# AT32F423 register map
Vendor: Keil; Series: AT32F423; File version: 1.0
CPU: CM4 r0p1, little endian, no MPU, FPU, 4 interrupt priority bits
Registers are 32-bit, read-write, reset 0x0 unless marked. A register's access mark holds for its fields unless they carry their own. Offsets are from the block's base; [hi:lo] are bit positions; 'fields as' and 'values as' point back to an identical list.

## XMC — Flexible static memory controller
Base 0xA0000000
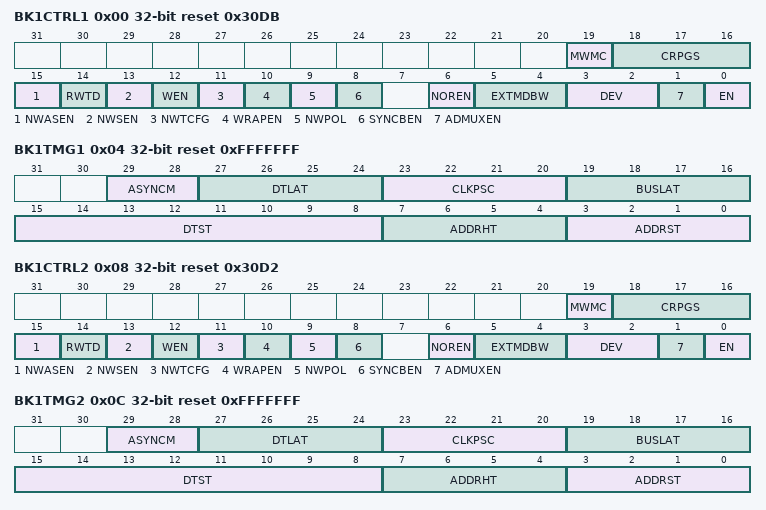
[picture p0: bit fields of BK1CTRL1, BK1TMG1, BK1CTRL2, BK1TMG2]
0x00 BK1CTRL1 reset 0x30DB — SRAM/NOR-Flash chip-select control register 1
  [19] MWMC — Memory write mode control
  [18:16] CRPGS — CRAM page size
  [15] NWASEN — NWAIT in asynchronous transfer enable
  [14] RWTD — Read-write timing different
  [13] NWSEN — NWAIT in synchronous transfer enable
  [12] WEN — Write enable
  [11] NWTCFG — Wait timing configuration
  [10] WRAPEN — Wrapped enable
  [9] NWPOL — NWAIT polarity
  [8] SYNCBEN — Synchronous burst enable
  [6] NOREN — Nor flash access enable
  [5:4] EXTMDBW — External memory data bus width
  [3:2] DEV — Memory device type
  [1] ADMUXEN — Address and data multiplexing enable
  [0] EN — Memory bank enable
0x04 BK1TMG1 reset 0xFFFFFFF — SRAM/NOR-Flash chip-select timing register 1
  [29:28] ASYNCM — Asynchronous mode
  [27:24] DTLAT — Data latency
  [23:20] CLKPSC — Clock prescale
  [19:16] BUSLAT — Bus latency
  [15:8] DTST — Asynchronous data setup time
  [7:4] ADDRHT — Address-hold time
  [3:0] ADDRST — Address setup time
0x08 BK1CTRL2 reset 0x30D2 — SRAM/NOR-Flash chip-select control register 2
  fields as BK1CTRL1
0x0C BK1TMG2 reset 0xFFFFFFF — SRAM/NOR-Flash chip-select timing register 2
  fields as BK1TMG1
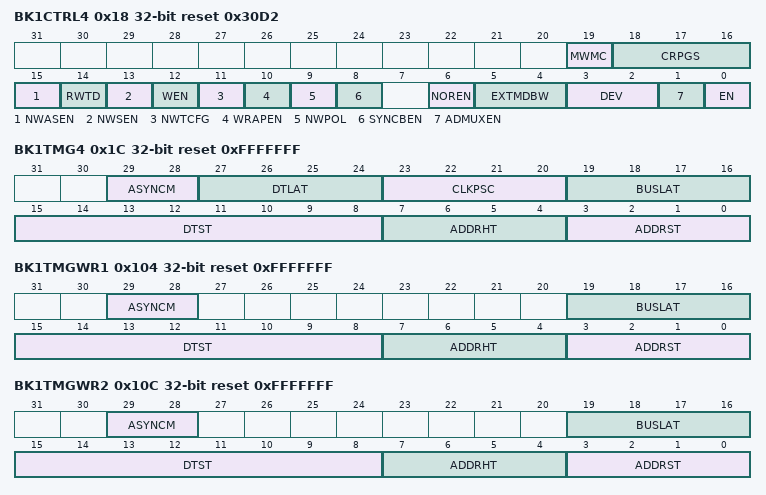
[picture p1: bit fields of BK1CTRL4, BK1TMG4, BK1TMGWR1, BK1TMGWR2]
0x18 BK1CTRL4 reset 0x30D2 — SRAM/NOR-Flash chip-select control register 4
  fields as BK1CTRL1
0x1C BK1TMG4 reset 0xFFFFFFF — SRAM/NOR-Flash chip-select timing register 4
  fields as BK1TMG1
0x104 BK1TMGWR1 reset 0xFFFFFFF — SRAM/NOR-Flash write timing registers 1
  [29:28] ASYNCM — Asynchronous mode
  [19:16] BUSLAT — Bus latency
  [15:8] DTST — Asynchronous data setup time
  [7:4] ADDRHT — Address-hold time
  [3:0] ADDRST — Address setup time
0x10C BK1TMGWR2 reset 0xFFFFFFF — SRAM/NOR-Flash write timing registers 2
  fields as BK1TMGWR1
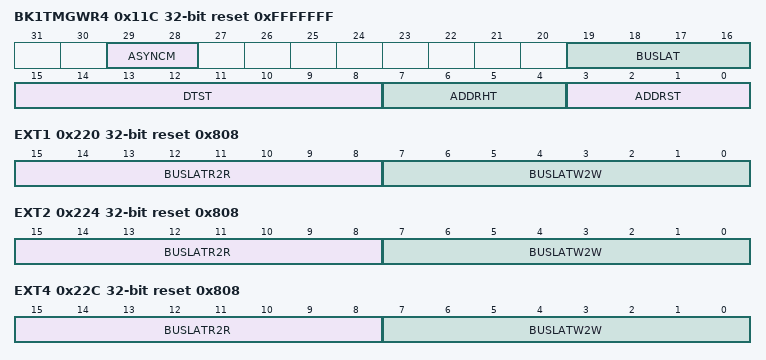
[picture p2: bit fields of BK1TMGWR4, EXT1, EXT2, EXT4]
0x11C BK1TMGWR4 reset 0xFFFFFFF — SRAM/NOR-Flash write timing registers 4
  fields as BK1TMGWR1
0x220 EXT1 reset 0x808 — externl timeing register 1
  [15:8] BUSLATR2R — Bus turnaround phase for consecutive read duration
  [7:0] BUSLATW2W — Bus turnaround phase for consecutive write duration
0x224 EXT2 reset 0x808 — externl timeing register 2
  fields as EXT1
0x22C EXT4 reset 0x808 — externl timeing register 4
  fields as EXT1

## PWC — Power control
Base 0x40007000
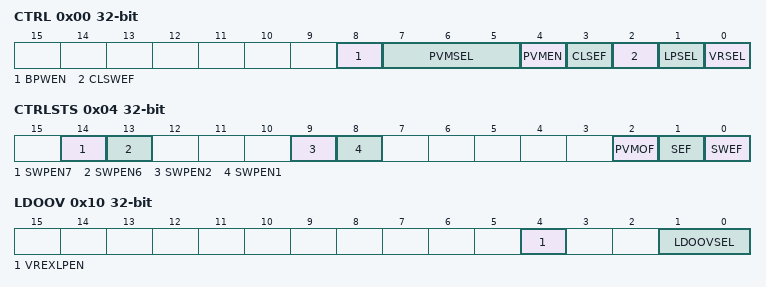
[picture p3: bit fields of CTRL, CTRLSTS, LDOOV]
0x00 CTRL — Power control register (PWC_CTRL)
  [8] BPWEN — Battery powered domain write enable
    0=Disabled (Battery powered domain write disabled); 1=Enabled (Battery powered domain write enabled)
  [7:5] PVMSEL — Power voltage monitoring boundary select
    1=v2_3 (2.3V); 2=v2_4 (2.4V); 3=v2_5 (2.5V); 4=v2_6 (2.6V); 5=v2_7 (2.7V); 6=v2_8 (2.8V); 7=v2_9 (2.9V)
  [4] PVMEN — Power voltage monitoring enable
    0=Disabled (Power voltage monitoring disabled); 1=Enabled (Power voltage monitoring enabled)
  [3] CLSEF wo write-1-clears — Clear SEF flag
    1=Clear the flag
  [2] CLSWEF wo write-1-clears — Clear SWEF flag
    1=Clear the flag
  [1] LPSEL — Low power mode select when Cortex-M4F sleepdeep
    0=Enter deepsleep mode when the CPU enters deepsleep mode; 1=Enter standby mode when the CPU enters deepsleep mode
  [0] VRSEL — Voltage regulator state select when deepsleep mode
    0=Enabled (LDO enabled in deepsleep mode); 1=Disabled (LDO disabled in deepsleep mode)
0x04 CTRLSTS — Power control and status register (PWC_CTRLSTS)
  [14] SWPEN7 — Standby wake-up pin 7 enable
    0=Disabled; 1=Enabled
  [13] SWPEN6 — Standby wake-up pin 6 enable
    0=Disabled; 1=Enabled
  [9] SWPEN2 — Standby wake-up pin 2 enable
    0=Disabled; 1=Enabled
  [8] SWPEN1 — Standby wake-up pin 1 enable
    0=Disabled; 1=Enabled
  [2] PVMOF ro — Power voltage monitoring output flag
    0=Higher (Power voltage is higher than the threshold); 1=Lower (Power voltage is lower than the threshold)
  [1] SEF ro — Standby mode entry flag
    0=NoStandby (Device is not in standby mode); 1=Standby (Device is in standby mode)
  [0] SWEF ro — Standby wake-up event flag
    0=No wakeup event occurred; 1=Wakeup event occurred
0x10 LDOOV — LDO output voltage register
  [4] VREXLPEN — Voltage regulator extra low power mode enable
  [1:0] LDOOVSEL — LDO output voltage select
